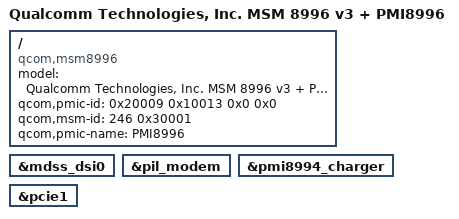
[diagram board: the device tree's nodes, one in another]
/* Copyright (c) 2019, The Linux Foundation. All rights reserved.
 *
 * This program is free software; you can redistribute it and/or modify
 * it under the terms of the GNU General Public License version 2 and
 * only version 2 as published by the Free Software Foundation.
 *
 * This program is distributed in the hope that it will be useful,
 * but WITHOUT ANY WARRANTY; without even the implied warranty of
 * MERCHANTABILITY or FITNESS FOR A PARTICULAR PURPOSE.  See the
 * GNU General Public License for more details.
 */

/dts-v1/;

#include "msm8996-v3.dtsi"
#include "msm-pmi8996.dtsi"

/ {
	model = "Qualcomm Technologies, Inc. MSM 8996 v3 + PMI8996";
	compatible = "qcom,msm8996";
	qcom,pmic-id = <0x20009 0x10013 0x0 0x0>;
	qcom,msm-id = <246 0x30001>;
	qcom,pmic-name = "PMI8996";
};

&mdss_dsi0 {
	/delete-property/qcom,null-insertion-enabled;
};

&pil_modem {
       /delete-property/ qcom,mx-spike-wa;
};

&pmi8994_charger {
        /delete-property/ qcom,charge-unknown-battery;
        /delete-property/ qcom,chg-inhibit-fg;
};

&pcie1 {
	   /delete-property/ perst-gpio;
	   /delete-property/ wake-gpio;
};
